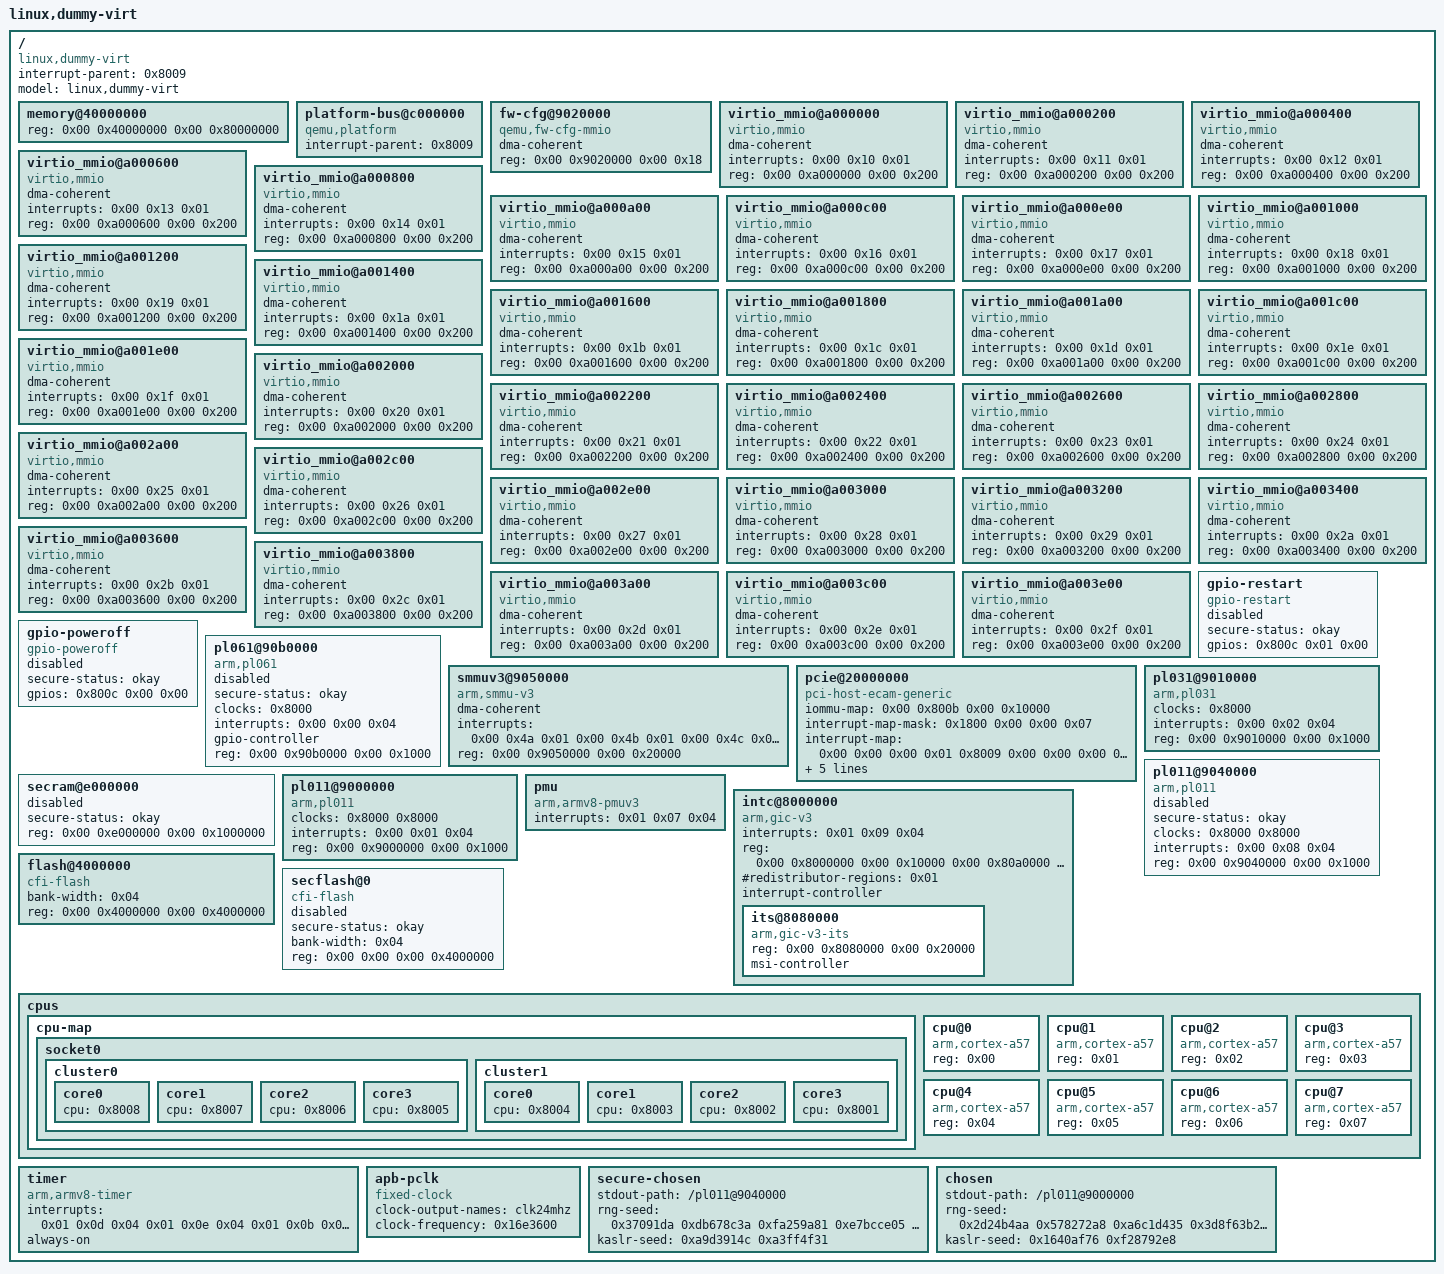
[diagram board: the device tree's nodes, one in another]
/dts-v1/;

/ {
	interrupt-parent = <0x8009>;
	model = "linux,dummy-virt";
	#size-cells = <0x02>;
	#address-cells = <0x02>;
	compatible = "linux,dummy-virt";

	memory@40000000 {
		reg = <0x00 0x40000000 0x00 0x80000000>;
		device_type = "memory";
	};

	platform-bus@c000000 {
		interrupt-parent = <0x8009>;
		ranges = <0x00 0x00 0xc000000 0x2000000>;
		#address-cells = <0x01>;
		#size-cells = <0x01>;
		compatible = "qemu,platform\0simple-bus";
	};

	fw-cfg@9020000 {
		dma-coherent;
		reg = <0x00 0x9020000 0x00 0x18>;
		compatible = "qemu,fw-cfg-mmio";
	};

	virtio_mmio@a000000 {
		dma-coherent;
		interrupts = <0x00 0x10 0x01>;
		reg = <0x00 0xa000000 0x00 0x200>;
		compatible = "virtio,mmio";
	};

	virtio_mmio@a000200 {
		dma-coherent;
		interrupts = <0x00 0x11 0x01>;
		reg = <0x00 0xa000200 0x00 0x200>;
		compatible = "virtio,mmio";
	};

	virtio_mmio@a000400 {
		dma-coherent;
		interrupts = <0x00 0x12 0x01>;
		reg = <0x00 0xa000400 0x00 0x200>;
		compatible = "virtio,mmio";
	};

	virtio_mmio@a000600 {
		dma-coherent;
		interrupts = <0x00 0x13 0x01>;
		reg = <0x00 0xa000600 0x00 0x200>;
		compatible = "virtio,mmio";
	};

	virtio_mmio@a000800 {
		dma-coherent;
		interrupts = <0x00 0x14 0x01>;
		reg = <0x00 0xa000800 0x00 0x200>;
		compatible = "virtio,mmio";
	};

	virtio_mmio@a000a00 {
		dma-coherent;
		interrupts = <0x00 0x15 0x01>;
		reg = <0x00 0xa000a00 0x00 0x200>;
		compatible = "virtio,mmio";
	};

	virtio_mmio@a000c00 {
		dma-coherent;
		interrupts = <0x00 0x16 0x01>;
		reg = <0x00 0xa000c00 0x00 0x200>;
		compatible = "virtio,mmio";
	};

	virtio_mmio@a000e00 {
		dma-coherent;
		interrupts = <0x00 0x17 0x01>;
		reg = <0x00 0xa000e00 0x00 0x200>;
		compatible = "virtio,mmio";
	};

	virtio_mmio@a001000 {
		dma-coherent;
		interrupts = <0x00 0x18 0x01>;
		reg = <0x00 0xa001000 0x00 0x200>;
		compatible = "virtio,mmio";
	};

	virtio_mmio@a001200 {
		dma-coherent;
		interrupts = <0x00 0x19 0x01>;
		reg = <0x00 0xa001200 0x00 0x200>;
		compatible = "virtio,mmio";
	};

	virtio_mmio@a001400 {
		dma-coherent;
		interrupts = <0x00 0x1a 0x01>;
		reg = <0x00 0xa001400 0x00 0x200>;
		compatible = "virtio,mmio";
	};

	virtio_mmio@a001600 {
		dma-coherent;
		interrupts = <0x00 0x1b 0x01>;
		reg = <0x00 0xa001600 0x00 0x200>;
		compatible = "virtio,mmio";
	};

	virtio_mmio@a001800 {
		dma-coherent;
		interrupts = <0x00 0x1c 0x01>;
		reg = <0x00 0xa001800 0x00 0x200>;
		compatible = "virtio,mmio";
	};

	virtio_mmio@a001a00 {
		dma-coherent;
		interrupts = <0x00 0x1d 0x01>;
		reg = <0x00 0xa001a00 0x00 0x200>;
		compatible = "virtio,mmio";
	};

	virtio_mmio@a001c00 {
		dma-coherent;
		interrupts = <0x00 0x1e 0x01>;
		reg = <0x00 0xa001c00 0x00 0x200>;
		compatible = "virtio,mmio";
	};

	virtio_mmio@a001e00 {
		dma-coherent;
		interrupts = <0x00 0x1f 0x01>;
		reg = <0x00 0xa001e00 0x00 0x200>;
		compatible = "virtio,mmio";
	};

	virtio_mmio@a002000 {
		dma-coherent;
		interrupts = <0x00 0x20 0x01>;
		reg = <0x00 0xa002000 0x00 0x200>;
		compatible = "virtio,mmio";
	};

	virtio_mmio@a002200 {
		dma-coherent;
		interrupts = <0x00 0x21 0x01>;
		reg = <0x00 0xa002200 0x00 0x200>;
		compatible = "virtio,mmio";
	};

	virtio_mmio@a002400 {
		dma-coherent;
		interrupts = <0x00 0x22 0x01>;
		reg = <0x00 0xa002400 0x00 0x200>;
		compatible = "virtio,mmio";
	};

	virtio_mmio@a002600 {
		dma-coherent;
		interrupts = <0x00 0x23 0x01>;
		reg = <0x00 0xa002600 0x00 0x200>;
		compatible = "virtio,mmio";
	};

	virtio_mmio@a002800 {
		dma-coherent;
		interrupts = <0x00 0x24 0x01>;
		reg = <0x00 0xa002800 0x00 0x200>;
		compatible = "virtio,mmio";
	};

	virtio_mmio@a002a00 {
		dma-coherent;
		interrupts = <0x00 0x25 0x01>;
		reg = <0x00 0xa002a00 0x00 0x200>;
		compatible = "virtio,mmio";
	};

	virtio_mmio@a002c00 {
		dma-coherent;
		interrupts = <0x00 0x26 0x01>;
		reg = <0x00 0xa002c00 0x00 0x200>;
		compatible = "virtio,mmio";
	};

	virtio_mmio@a002e00 {
		dma-coherent;
		interrupts = <0x00 0x27 0x01>;
		reg = <0x00 0xa002e00 0x00 0x200>;
		compatible = "virtio,mmio";
	};

	virtio_mmio@a003000 {
		dma-coherent;
		interrupts = <0x00 0x28 0x01>;
		reg = <0x00 0xa003000 0x00 0x200>;
		compatible = "virtio,mmio";
	};

	virtio_mmio@a003200 {
		dma-coherent;
		interrupts = <0x00 0x29 0x01>;
		reg = <0x00 0xa003200 0x00 0x200>;
		compatible = "virtio,mmio";
	};

	virtio_mmio@a003400 {
		dma-coherent;
		interrupts = <0x00 0x2a 0x01>;
		reg = <0x00 0xa003400 0x00 0x200>;
		compatible = "virtio,mmio";
	};

	virtio_mmio@a003600 {
		dma-coherent;
		interrupts = <0x00 0x2b 0x01>;
		reg = <0x00 0xa003600 0x00 0x200>;
		compatible = "virtio,mmio";
	};

	virtio_mmio@a003800 {
		dma-coherent;
		interrupts = <0x00 0x2c 0x01>;
		reg = <0x00 0xa003800 0x00 0x200>;
		compatible = "virtio,mmio";
	};

	virtio_mmio@a003a00 {
		dma-coherent;
		interrupts = <0x00 0x2d 0x01>;
		reg = <0x00 0xa003a00 0x00 0x200>;
		compatible = "virtio,mmio";
	};

	virtio_mmio@a003c00 {
		dma-coherent;
		interrupts = <0x00 0x2e 0x01>;
		reg = <0x00 0xa003c00 0x00 0x200>;
		compatible = "virtio,mmio";
	};

	virtio_mmio@a003e00 {
		dma-coherent;
		interrupts = <0x00 0x2f 0x01>;
		reg = <0x00 0xa003e00 0x00 0x200>;
		compatible = "virtio,mmio";
	};

	gpio-restart {
		secure-status = "okay";
		status = "disabled";
		gpios = <0x800c 0x01 0x00>;
		compatible = "gpio-restart";
	};

	gpio-poweroff {
		secure-status = "okay";
		status = "disabled";
		gpios = <0x800c 0x00 0x00>;
		compatible = "gpio-poweroff";
	};

	pl061@90b0000 {
		secure-status = "okay";
		status = "disabled";
		phandle = <0x800c>;
		clock-names = "apb_pclk";
		clocks = <0x8000>;
		interrupts = <0x00 0x00 0x04>;
		gpio-controller;
		#gpio-cells = <0x02>;
		compatible = "arm,pl061\0arm,primecell";
		reg = <0x00 0x90b0000 0x00 0x1000>;
	};

	smmuv3@9050000 {
		phandle = <0x800b>;
		#iommu-cells = <0x01>;
		dma-coherent;
		interrupt-names = "eventq\0priq\0cmdq-sync\0gerror";
		interrupts = <0x00 0x4a 0x01 0x00 0x4b 0x01 0x00 0x4c 0x01 0x00 0x4d 0x01>;
		reg = <0x00 0x9050000 0x00 0x20000>;
		compatible = "arm,smmu-v3";
	};

	pcie@20000000 {
		iommu-map = <0x00 0x800b 0x00 0x10000>;
		interrupt-map-mask = <0x1800 0x00 0x00 0x07>;
		interrupt-map = <0x00 0x00 0x00 0x01 0x8009 0x00 0x00 0x00 0x03 0x04 0x00 0x00 0x00 0x02 0x8009 0x00 0x00 0x00 0x04 0x04 0x00 0x00 0x00 0x03 0x8009 0x00 0x00 0x00 0x05 0x04 0x00 0x00 0x00 0x04 0x8009 0x00 0x00 0x00 0x06 0x04 0x800 0x00 0x00 0x01 0x8009 0x00 0x00 0x00 0x04 0x04 0x800 0x00 0x00 0x02 0x8009 0x00 0x00 0x00 0x05 0x04 0x800 0x00 0x00 0x03 0x8009 0x00 0x00 0x00 0x06 0x04 0x800 0x00 0x00 0x04 0x8009 0x00 0x00 0x00 0x03 0x04 0x1000 0x00 0x00 0x01 0x8009 0x00 0x00 0x00 0x05 0x04 0x1000 0x00 0x00 0x02 0x8009 0x00 0x00 0x00 0x06 0x04 0x1000 0x00 0x00 0x03 0x8009 0x00 0x00 0x00 0x03 0x04 0x1000 0x00 0x00 0x04 0x8009 0x00 0x00 0x00 0x04 0x04 0x1800 0x00 0x00 0x01 0x8009 0x00 0x00 0x00 0x06 0x04 0x1800 0x00 0x00 0x02 0x8009 0x00 0x00 0x00 0x03 0x04 0x1800 0x00 0x00 0x03 0x8009 0x00 0x00 0x00 0x04 0x04 0x1800 0x00 0x00 0x04 0x8009 0x00 0x00 0x00 0x05 0x04>;
		#interrupt-cells = <0x01>;
		ranges = <0x1000000 0x00 0x00 0x00 0x3eff0000 0x00 0x10000 0x2000000 0x00 0x20000000 0x00 0x20000000 0x00 0x1eff0000 0x3000000 0x80 0x00 0x80 0x00 0x80 0x00>;
		reg = <0x40 0x10000000 0x00 0x10000000>;
		msi-map = <0x00 0x800a 0x00 0x10000>;
		dma-coherent;
		bus-range = <0x00 0xff>;
		linux,pci-domain = <0x00>;
		#size-cells = <0x02>;
		#address-cells = <0x03>;
		device_type = "pci";
		compatible = "pci-host-ecam-generic";
	};

	pl031@9010000 {
		clock-names = "apb_pclk";
		clocks = <0x8000>;
		interrupts = <0x00 0x02 0x04>;
		reg = <0x00 0x9010000 0x00 0x1000>;
		compatible = "arm,pl031\0arm,primecell";
	};

	pl011@9040000 {
		secure-status = "okay";
		status = "disabled";
		clock-names = "uartclk\0apb_pclk";
		clocks = <0x8000 0x8000>;
		interrupts = <0x00 0x08 0x04>;
		reg = <0x00 0x9040000 0x00 0x1000>;
		compatible = "arm,pl011\0arm,primecell";
	};

	secram@e000000 {
		secure-status = "okay";
		status = "disabled";
		reg = <0x00 0xe000000 0x00 0x1000000>;
		device_type = "memory";
	};

	pl011@9000000 {
		clock-names = "uartclk\0apb_pclk";
		clocks = <0x8000 0x8000>;
		interrupts = <0x00 0x01 0x04>;
		reg = <0x00 0x9000000 0x00 0x1000>;
		compatible = "arm,pl011\0arm,primecell";
	};

	pmu {
		interrupts = <0x01 0x07 0x04>;
		compatible = "arm,armv8-pmuv3";
	};

	intc@8000000 {
		phandle = <0x8009>;
		interrupts = <0x01 0x09 0x04>;
		reg = <0x00 0x8000000 0x00 0x10000 0x00 0x80a0000 0x00 0xf60000>;
		#redistributor-regions = <0x01>;
		compatible = "arm,gic-v3";
		ranges;
		#size-cells = <0x02>;
		#address-cells = <0x02>;
		interrupt-controller;
		#interrupt-cells = <0x03>;

		its@8080000 {
			phandle = <0x800a>;
			reg = <0x00 0x8080000 0x00 0x20000>;
			#msi-cells = <0x01>;
			msi-controller;
			compatible = "arm,gic-v3-its";
		};
	};

	flash@4000000 {
		bank-width = <0x04>;
		reg = <0x00 0x4000000 0x00 0x4000000>;
		compatible = "cfi-flash";
	};

	secflash@0 {
		secure-status = "okay";
		status = "disabled";
		bank-width = <0x04>;
		reg = <0x00 0x00 0x00 0x4000000>;
		compatible = "cfi-flash";
	};

	cpus {
		#size-cells = <0x00>;
		#address-cells = <0x01>;

		cpu-map {

			socket0 {

				cluster0 {

					core0 {
						cpu = <0x8008>;
					};

					core1 {
						cpu = <0x8007>;
					};

					core2 {
						cpu = <0x8006>;
					};

					core3 {
						cpu = <0x8005>;
					};
				};

				cluster1 {

					core0 {
						cpu = <0x8004>;
					};

					core1 {
						cpu = <0x8003>;
					};

					core2 {
						cpu = <0x8002>;
					};

					core3 {
						cpu = <0x8001>;
					};
				};
			};
		};

		cpu@0 {
			phandle = <0x8008>;
			reg = <0x00>;
			compatible = "arm,cortex-a57";
			device_type = "cpu";
		};

		cpu@1 {
			phandle = <0x8007>;
			reg = <0x01>;
			compatible = "arm,cortex-a57";
			device_type = "cpu";
		};

		cpu@2 {
			phandle = <0x8006>;
			reg = <0x02>;
			compatible = "arm,cortex-a57";
			device_type = "cpu";
		};

		cpu@3 {
			phandle = <0x8005>;
			reg = <0x03>;
			compatible = "arm,cortex-a57";
			device_type = "cpu";
		};

		cpu@4 {
			phandle = <0x8004>;
			reg = <0x04>;
			compatible = "arm,cortex-a57";
			device_type = "cpu";
		};

		cpu@5 {
			phandle = <0x8003>;
			reg = <0x05>;
			compatible = "arm,cortex-a57";
			device_type = "cpu";
		};

		cpu@6 {
			phandle = <0x8002>;
			reg = <0x06>;
			compatible = "arm,cortex-a57";
			device_type = "cpu";
		};

		cpu@7 {
			phandle = <0x8001>;
			reg = <0x07>;
			compatible = "arm,cortex-a57";
			device_type = "cpu";
		};
	};

	timer {
		interrupts = <0x01 0x0d 0x04 0x01 0x0e 0x04 0x01 0x0b 0x04 0x01 0x0a 0x04>;
		always-on;
		compatible = "arm,armv8-timer\0arm,armv7-timer";
	};

	apb-pclk {
		phandle = <0x8000>;
		clock-output-names = "clk24mhz";
		clock-frequency = <0x16e3600>;
		#clock-cells = <0x00>;
		compatible = "fixed-clock";
	};

	secure-chosen {
		stdout-path = "/pl011@9040000";
		rng-seed = <0x37091da 0xdb678c3a 0xfa259a81 0xe7bcce05 0x1d620ab4 0xce4594c8 0x59ca5145 0x96639b88>;
		kaslr-seed = <0xa9d3914c 0xa3ff4f31>;
	};

	chosen {
		stdout-path = "/pl011@9000000";
		rng-seed = <0x2d24b4aa 0x578272a8 0xa6c1d435 0x3d8f63b2 0x4ec1914 0x676cea5b 0xc41b0600 0xd72333fa>;
		kaslr-seed = <0x1640af76 0xf28792e8>;
	};
};
